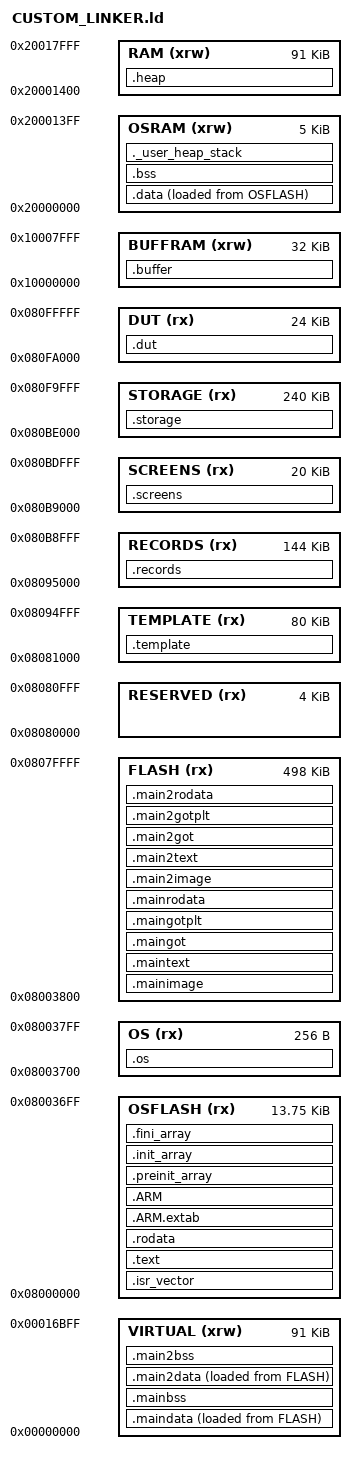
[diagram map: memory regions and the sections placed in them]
/*
******************************************************************************
**
**  File        : LinkerScript.ld
**
**  Author		: Auto-generated by STM32CubeIDE
**
**  Abstract    : Linker script for STM32L476ZGTx Device from STM32L4 series
**                      1024Kbytes FLASH
**                      96Kbytes RAM
**                      32Kbytes RAM2
**
**                Set heap size, stack size and stack location according
**                to application requirements.
**
**                Set memory bank area and size if external memory is used.
**
**  Target      : STMicroelectronics STM32
**
**  Distribution: The file is distributed as is without any warranty
**                of any kind.
**
*****************************************************************************
** @attention
**
** <h2><center>&copy; COPYRIGHT(c) 2020 STMicroelectronics</center></h2>
**
** Redistribution and use in source and binary forms, with or without modification,
** are permitted provided that the following conditions are met:
**   1. Redistributions of source code must retain the above copyright notice,
**      this list of conditions and the following disclaimer.
**   2. Redistributions in binary form must reproduce the above copyright notice,
**      this list of conditions and the following disclaimer in the documentation
**      and/or other materials provided with the distribution.
**   3. Neither the name of STMicroelectronics nor the names of its contributors
**      may be used to endorse or promote products derived from this software
**      without specific prior written permission.
**
** THIS SOFTWARE IS PROVIDED BY THE COPYRIGHT HOLDERS AND CONTRIBUTORS "AS IS"
** AND ANY EXPRESS OR IMPLIED WARRANTIES, INCLUDING, BUT NOT LIMITED TO, THE
** IMPLIED WARRANTIES OF MERCHANTABILITY AND FITNESS FOR A PARTICULAR PURPOSE ARE
** DISCLAIMED. IN NO EVENT SHALL THE COPYRIGHT HOLDER OR CONTRIBUTORS BE LIABLE
** FOR ANY DIRECT, INDIRECT, INCIDENTAL, SPECIAL, EXEMPLARY, OR CONSEQUENTIAL
** DAMAGES (INCLUDING, BUT NOT LIMITED TO, PROCUREMENT OF SUBSTITUTE GOODS OR
** SERVICES; LOSS OF USE, DATA, OR PROFITS; OR BUSINESS INTERRUPTION) HOWEVER
** CAUSED AND ON ANY THEORY OF LIABILITY, WHETHER IN CONTRACT, STRICT LIABILITY,
** OR TORT (INCLUDING NEGLIGENCE OR OTHERWISE) ARISING IN ANY WAY OUT OF THE USE
** OF THIS SOFTWARE, EVEN IF ADVISED OF THE POSSIBILITY OF SUCH DAMAGE.
**
*****************************************************************************
*/

/* Entry Point */
ENTRY(Reset_Handler)

/* Highest address of the user mode stack */
_estack = 0x20018000;	/* end of "RAM" Ram type memory */

_Min_Heap_Size = 0x100 ;	/* required amount of heap  */
_Min_Stack_Size = 0x100 ;	/* required amount of stack */

/* Memories definition */
MEMORY
{
    VIRTUAL	(xrw)	: ORIGIN = 0x00000000,	LENGTH = 91K
    OSRAM	(xrw)	: ORIGIN = 0x20000000,	LENGTH = 5K
    RAM		(xrw)	: ORIGIN = 0x20001400,	LENGTH = 91K
    BUFFRAM	(xrw)	: ORIGIN = 0x10000000,	LENGTH = 32K
    OSFLASH (rx)	: ORIGIN = 0x08000000,	LENGTH = 14080
    OS 		(rx)	: ORIGIN = 0x08003700,	LENGTH = 256
    FLASH	(rx)	: ORIGIN = 0x08003800,	LENGTH = 498K
    RESERVED(rx)	: ORIGIN = 0x08080000,	LENGTH = 4K
    TEMPLATE(rx)	: ORIGIN = 0x08081000,	LENGTH = 80K
    RECORDS	(rx)	: ORIGIN = 0x08095000,	LENGTH = 144K
    SCREENS	(rx)	: ORIGIN = 0x080B9000,	LENGTH = 20K
    STORAGE (rx)	: ORIGIN = 0x080BE000,	LENGTH = 240K
    DUT		(rx)	: ORIGIN = 0x080FA000,	LENGTH = 24K
}

/* Sections */
SECTIONS
{
   .mainimage :
   {
  	KEEP(*(.mainImageSection))
   }>FLASH
   
   _main_image = LOADADDR(.mainimage);
   
   .maintext :
   {
   	. = ALIGN(4);
    *main/*(.text)           /* .text sections (code) */
    *main/*(.text*)          /* .text* sections (code) */
    *main/*(.glue_7)         /* glue arm to thumb code */
    *main/*(.glue_7t)        /* glue thumb to arm code */
    *main/*(.eh_frame)
   	. = ALIGN(4);
   } >FLASH
   
   .maingot :
   {
    . = ALIGN(4);
    __main_got_start = .;
     *main/(.got)
     __main_got_end = .;
    . = ALIGN(4);
   } >FLASH
   
   _main_got_size = __main_got_end - __main_got_start;
   
   .maingotplt :
   {
    . = ALIGN(4);
     *(.got.plt)
    . = ALIGN(4);
   } >FLASH
   
   .mainrodata :
   {
    . = ALIGN(4);
    *main/*(.rodata)         /* .rodata sections (constants, strings, etc.) */
    *main/*(.rodata*)        /* .rodata* sections (constants, strings, etc.) */
    . = ALIGN(4);
   } >FLASH
   
   .maindata :
   {
    . = ALIGN(4);
    __main_data_start = .;
    *main/*(.data)         /* .data sections */
    *main/*(.data*)        /* .data* sections */
    __main_data_end = .;
    . = ALIGN(4);
   } >VIRTUAL AT> FLASH
   
   _mainsidata = LOADADDR(.maindata);
   
   _main_data_size = __main_data_end - __main_data_start;
   
   .mainbss :
   {
    . = ALIGN(4);
    __main_bss_start = .;
    *main/*(.bss)         /* .bss sections */
    *main/*(.bss*)        /* .bss* sections  */
    *main/*(COMMON)
    __main_bss_end = .;
    . = ALIGN(4);
   } >VIRTUAL
   
   _main_bss_size = __main_bss_end - __main_bss_start;
   
   .main2image :
   {
  	KEEP(*(.main2ImageSection))
   }>FLASH
   
   _main2_image = LOADADDR(.main2image);
   
   .main2text :
   {
   	. = ALIGN(4);
    *main2/*(.text)           /* .text sections (code) */
    *main2/*(.text*)          /* .text* sections (code) */
    *main2/*(.glue_7)         /* glue arm to thumb code */
    *main2/*(.glue_7t)        /* glue thumb to arm code */
    *main2/*(.eh_frame)
   	. = ALIGN(4);
   } >FLASH
   
   .main2got :
   {
    . = ALIGN(4);
    __main2_got_start = .;
     *(.got)
     __main2_got_end = .;
    . = ALIGN(4);
   } >FLASH
   
   _main2_got_size = __main2_got_end - __main2_got_start;
   
   .main2gotplt :
   {
    . = ALIGN(4);
     *(.got.plt)
    . = ALIGN(4);
   } >FLASH
   
   .main2rodata :
   {
    . = ALIGN(4);
    *main2/*(.rodata)         /* .rodata sections (constants, strings, etc.) */
    *main2/*(.rodata*)        /* .rodata* sections (constants, strings, etc.) */
    . = ALIGN(4);
   } >FLASH
   
   .main2data :
   {
    . = ALIGN(4);
    __main2_data_start = .;
    *main2/*(.data)         /* .data sections */
    *main2/*(.data*)        /* .data* sections */
    __main2_data_end = .;
    . = ALIGN(4);
   } >VIRTUAL AT> FLASH
   
   _main2sidata = LOADADDR(.main2data);
   
   _main2_data_size = __main2_data_end - __main2_data_start;
   
   .main2bss :
   {
    . = ALIGN(4);
    __main2_bss_start = .;
    *main2/*(.bss)         /* .bss sections */
    *main2/*(.bss*)        /* .bss* sections  */
    *main2/*(COMMON)
    __main2_bss_end = .;
    . = ALIGN(4);
   } >VIRTUAL
   
   _main2_bss_size = __main2_bss_end - __main2_bss_start;

  /* The startup code into "FLASH" Rom type memory */
  .isr_vector :
  {
    . = ALIGN(4);
    KEEP(*(.isr_vector)) /* Startup code */
    . = ALIGN(4);
  } >OSFLASH

  /* The program code and other data into "FLASH" Rom type memory */
  .text :
  {
    . = ALIGN(4);
    *(.text)           /* .text sections (code) */
    *(.text*)          /* .text* sections (code) */
    *(.glue_7)         /* glue arm to thumb code */
    *(.glue_7t)        /* glue thumb to arm code */
    *(.eh_frame)

    KEEP (*(.init))
    KEEP (*(.fini))

    . = ALIGN(4);
    _etext = .;        /* define a global symbols at end of code */
  } >OSFLASH

  /* Constant data into "FLASH" Rom type memory */
  .rodata :
  {
    . = ALIGN(4);
    *(.rodata)         /* .rodata sections (constants, strings, etc.) */
    *(.rodata*)        /* .rodata* sections (constants, strings, etc.) */
    . = ALIGN(4);
  } >OSFLASH

  .ARM.extab   : { 
  	. = ALIGN(4);
  	*(.ARM.extab* .gnu.linkonce.armextab.*)
  	. = ALIGN(4);
  } >OSFLASH
  
  .ARM : {
    . = ALIGN(4);
    __exidx_start = .;
    *(.ARM.exidx*)
    __exidx_end = .;
    . = ALIGN(4);
  } >OSFLASH

  .preinit_array     :
  {
    . = ALIGN(4);
    PROVIDE_HIDDEN (__preinit_array_start = .);
    KEEP (*(.preinit_array*))
    PROVIDE_HIDDEN (__preinit_array_end = .);
    . = ALIGN(4);
  } >OSFLASH
  
  .init_array :
  {
    . = ALIGN(4);
    PROVIDE_HIDDEN (__init_array_start = .);
    KEEP (*(SORT(.init_array.*)))
    KEEP (*(.init_array*))
    PROVIDE_HIDDEN (__init_array_end = .);
    . = ALIGN(4);
  } >OSFLASH
  
  .fini_array :
  {
    . = ALIGN(4);
    PROVIDE_HIDDEN (__fini_array_start = .);
    KEEP (*(SORT(.fini_array.*)))
    KEEP (*(.fini_array*))
    PROVIDE_HIDDEN (__fini_array_end = .);
    . = ALIGN(4);
  } >OSFLASH

  /* Used by the startup to initialize data */
  _sidata = LOADADDR(.data);
  
  _got = LOADADDR(.maingot);

  /* Initialized data sections into "RAM" Ram type memory */
  .data : 
  {
    . = ALIGN(4);
    _sdata = .;        /* create a global symbol at data start */
    *(.data)           /* .data sections */
    *(.data*)          /* .data* sections */
    . = ALIGN(4);
    _edata = .;        /* define a global symbol at data end */
    
  } >OSRAM AT> OSFLASH
  
  /* Uninitialized data section into "RAM" Ram type memory */
  . = ALIGN(4);
  .bss :
  {
    /* This is used by the startup in order to initialize the .bss secion */
    _sbss = .;         /* define a global symbol at bss start */
    __bss_start__ = _sbss;
    *(.bss)
    *(.bss*)
    *(COMMON)

    . = ALIGN(4);
    _ebss = .;         /* define a global symbol at bss end */
    __bss_end__ = _ebss;
  } >OSRAM

  /* User_heap_stack section, used to check that there is enough "RAM" Ram  type memory left */
  ._user_heap_stack :
  {
    . = ALIGN(8);
    PROVIDE ( end = . );
    PROVIDE ( _end = . );
    . = . + _Min_Heap_Size;
    . = . + _Min_Stack_Size;
    . = ALIGN(8);
  } >OSRAM
  
  _heap = LOADADDR(.heap);
  
  .heap :
  {
  	. = ALIGN(8);
  }>RAM
  
  
  /*os Section*/
  .os :
  {
  	KEEP(*(.osSection))
  }>OS
  
  _os = LOADADDR(.os);
  
  /*buffer Section*/
  .buffer :
  {
  	KEEP(*(.bufferSection))
  }>BUFFRAM
  
  /*template Section*/
  .template :
  {
  	KEEP(*(.templateSection))
  }>TEMPLATE
  
  /*Records Section*/
  .records :
  {
  	KEEP(*(.recordsSection))
  }>RECORDS
  
  /*Screens Section*/
  .screens :
  {
  	KEEP(*(.screensSection))
  }>SCREENS
  
  /*Storage Section*/
  .storage :
  {
  	KEEP(*(.storageSection))
  }>STORAGE
  
  /*Dut Section*/
  .dut :
  {
  	KEEP(*(.dutSection))
  }>DUT

  /* Remove information from the compiler libraries */
  /DISCARD/ :
  {
    libc.a ( * )
    libm.a ( * )
    libgcc.a ( * )
  }

  .ARM.attributes 0 : { *(.ARM.attributes) }
}
